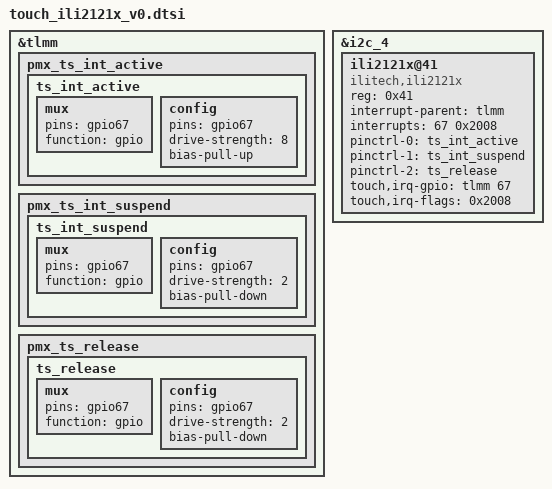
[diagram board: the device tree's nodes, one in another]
&tlmm{
		/delete-node/ts_mux;
		
		pmx_ts_int_active {
			ts_int_active: ts_int_active {
				mux {
					pins = "gpio67";
					function = "gpio";
				};

				config {
					pins = "gpio67";
					drive-strength = <8>;
					bias-pull-up;
				};
			};
		};

		pmx_ts_int_suspend {
			ts_int_suspend: ts_int_suspend {
				mux {
					pins = "gpio67";
					function = "gpio";
				};

				config {
					pins = "gpio67";
					drive-strength = <2>;
					bias-pull-down;
				};
			};
		};

		pmx_ts_release {
			ts_release: ts_release {
				mux {
					pins = "gpio67";
					function = "gpio";
				};

				config {
					pins = "gpio67";
					drive-strength = <2>;
					bias-pull-down;
				};
			};
		};
};

&i2c_4 {
        status = "okay";

	ili2121x@41 {
		compatible = "ilitech,ili2121x";
		reg = <0x41>;
		interrupt-parent = <&tlmm>;
		interrupts = <67 0x2008>;
		/* pins used by touchscreen */
		pinctrl-names = "pmx_ts_active",
		"pmx_ts_suspend",
		"pmx_ts_release";
			//pinctrl-0 = <&ts_int_active &ts_reset_active>;
			//pinctrl-1 = <&ts_int_suspend &ts_reset_suspend>;
		pinctrl-0 = <&ts_int_active>;
		pinctrl-1 = <&ts_int_suspend>;
		pinctrl-2 = <&ts_release>;
		touch,irq-gpio  = <&tlmm 67 0x2008>;
		touch,irq-flags = <0x2008>;
			//touch,reset-gpio = <&tlmm 64 0x00>;
	};
};
